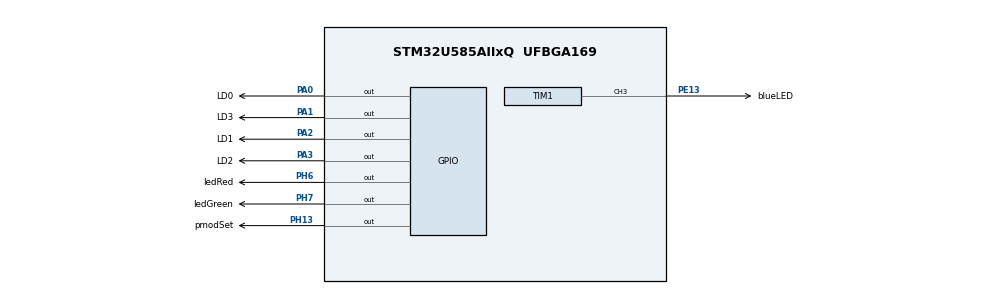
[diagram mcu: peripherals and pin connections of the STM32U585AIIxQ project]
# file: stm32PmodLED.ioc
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CORTEX_M33_NS.userName=CORTEX_M33
Mcu.Family=STM32U5
Mcu.Name=STM32U585AIIxQ
Mcu.Package=UFBGA169
NVIC.PriorityGroup=NVIC_PRIORITYGROUP_4
PA0.GPIO_Label=LD0
PA0.Signal=GPIO_Output
PA1.GPIO_Label=LD3
PA1.Signal=GPIO_Output
PA2.GPIO_Label=LD1
PA2.Signal=GPIO_Output
PA3.GPIO_Label=LD2
PA3.Signal=GPIO_Output
PE13.GPIO_Label=blueLED
PE13.Signal=S_TIM1_CH3
PH13.GPIO_Label=pmodSet
PH13.Signal=GPIO_Output
PH6.GPIO_Label=ledRed
PH6.Signal=GPIO_Output
PH7.GPIO_Label=ledGreen
PH7.Signal=GPIO_Output
ProjectManager.HeapSize=0x200
ProjectManager.StackSize=0x400
ProjectManager.TargetToolchain=STM32CubeIDE
RCC.ADCFreq_Value=16000000
RCC.EPOD_VALUE=4000000
RCC.HSE_VALUE=16000000
RCC.HSI48_VALUE=48000000
RCC.HSI_VALUE=16000000
RCC.LSE_VALUE=32768
RCC.LSIDIV_VALUE=32000
RCC.MSI_VALUE=4000000
RCC.USBFreq_Value=48000000
RCC.VCOOutputFreq_Value=516000000
SH.S_TIM1_CH3.0=TIM1_CH3,PWM Generation3 CH3
TIM1.Channel-PWM\ Generation3\ CH3=TIM_CHANNEL_3
TIM1.PeriodNoDither=999
TIM1.Prescaler=3
VP_LPBAMQUEUE_VS_QUEUE.Mode=QUEUEMODE
VP_LPBAM_VS_SIG1.Mode=SmartRun
VP_LPBAM_VS_SIG4.Mode=LPDMA1
VP_MEMORYMAP_VS_MEMORYMAP.Mode=CurAppReg
VP_PWR_VS_SECSignals.Mode=Security/Privilege
board=custom

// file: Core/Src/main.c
/* USER CODE BEGIN Header */
/**
  ******************************************************************************
  * @file           : main.c
  * @brief          : Main program body
  ******************************************************************************
  * @attention
  *
  * Copyright (c) 2025 STMicroelectronics.
  * All rights reserved.
  *
  * This software is licensed under terms that can be found in the LICENSE file
  * in the root directory of this software component.
  * If no LICENSE file comes with this software, it is provided AS-IS.
  *
  ******************************************************************************
  */
/* USER CODE END Header */
#include "main.h"

TIM_HandleTypeDef htim1;

void SystemClock_Config(void);
static void MX_GPIO_Init(void);
static void MX_TIM1_Init(void);

int main(void)
{

  /* MCU Configuration--------------------------------------------------------*/

  /* Reset of all peripherals, Initializes the Flash interface and the Systick. */
  HAL_Init();

  /* Configure the system clock */
  SystemClock_Config();

  /* Initialize all configured peripherals */
  MX_GPIO_Init();
  MX_TIM1_Init();
  /* USER CODE BEGIN 2 */
  HAL_GPIO_WritePin(GPIOH, pmodSet_Pin, GPIO_PIN_SET);
  HAL_GPIO_WritePin(GPIOA, LD0_Pin|LD3_Pin|LD1_Pin|LD2_Pin, GPIO_PIN_RESET);
  HAL_GPIO_WritePin(GPIOH, ledRed_Pin|ledGreen_Pin, GPIO_PIN_SET);
  /* USER CODE END 2 */

  /* Infinite loop */
  /* USER CODE BEGIN WHILE */
  HAL_TIM_PWM_Start(&htim1, TIM_CHANNEL_3);
  while (1)
  {
    /* USER CODE END WHILE */

    /* USER CODE BEGIN 3 */
	  for(int i = 0; i < 1000; i++)
	  {
		  __HAL_TIM_SET_COMPARE(&htim1, TIM_CHANNEL_3, i);
		  HAL_Delay(1);
	  }
	  for(int i = 1000; i > 0; i--)
	  {
		  __HAL_TIM_SET_COMPARE(&htim1, TIM_CHANNEL_3, i);
		  HAL_Delay(1);
	  }
  }
  /* USER CODE END 3 */
}

void SystemClock_Config(void)
{
  RCC_OscInitTypeDef RCC_OscInitStruct = {0};
  RCC_ClkInitTypeDef RCC_ClkInitStruct = {0};

  /** Configure the main internal regulator output voltage
  */
  if (HAL_PWREx_ControlVoltageScaling(PWR_REGULATOR_VOLTAGE_SCALE4) != HAL_OK)
  {
    Error_Handler();
  }

  /** Initializes the CPU, AHB and APB buses clocks
  */
  RCC_OscInitStruct.OscillatorType = RCC_OSCILLATORTYPE_MSI;
  RCC_OscInitStruct.MSIState = RCC_MSI_ON;
  RCC_OscInitStruct.MSICalibrationValue = RCC_MSICALIBRATION_DEFAULT;
  RCC_OscInitStruct.MSIClockRange = RCC_MSIRANGE_4;
  RCC_OscInitStruct.PLL.PLLState = RCC_PLL_NONE;
  if (HAL_RCC_OscConfig(&RCC_OscInitStruct) != HAL_OK)
  {
    Error_Handler();
  }

  /** Initializes the CPU, AHB and APB buses clocks
  */
  RCC_ClkInitStruct.ClockType = RCC_CLOCKTYPE_HCLK|RCC_CLOCKTYPE_SYSCLK
                              |RCC_CLOCKTYPE_PCLK1|RCC_CLOCKTYPE_PCLK2
                              |RCC_CLOCKTYPE_PCLK3;
  RCC_ClkInitStruct.SYSCLKSource = RCC_SYSCLKSOURCE_MSI;
  RCC_ClkInitStruct.AHBCLKDivider = RCC_SYSCLK_DIV1;
  RCC_ClkInitStruct.APB1CLKDivider = RCC_HCLK_DIV1;
  RCC_ClkInitStruct.APB2CLKDivider = RCC_HCLK_DIV1;
  RCC_ClkInitStruct.APB3CLKDivider = RCC_HCLK_DIV1;

  if (HAL_RCC_ClockConfig(&RCC_ClkInitStruct, FLASH_LATENCY_0) != HAL_OK)
  {
    Error_Handler();
  }
}

static void MX_TIM1_Init(void)
{

  TIM_MasterConfigTypeDef sMasterConfig = {0};
  TIM_OC_InitTypeDef sConfigOC = {0};
  TIM_BreakDeadTimeConfigTypeDef sBreakDeadTimeConfig = {0};

  htim1.Instance = TIM1;
  htim1.Init.Prescaler = 3;
  htim1.Init.CounterMode = TIM_COUNTERMODE_UP;
  htim1.Init.Period = 999;
  htim1.Init.ClockDivision = TIM_CLOCKDIVISION_DIV1;
  htim1.Init.RepetitionCounter = 0;
  htim1.Init.AutoReloadPreload = TIM_AUTORELOAD_PRELOAD_DISABLE;
  if (HAL_TIM_PWM_Init(&htim1) != HAL_OK)
  {
    Error_Handler();
  }
  sMasterConfig.MasterOutputTrigger = TIM_TRGO_RESET;
  sMasterConfig.MasterOutputTrigger2 = TIM_TRGO2_RESET;
  sMasterConfig.MasterSlaveMode = TIM_MASTERSLAVEMODE_DISABLE;
  if (HAL_TIMEx_MasterConfigSynchronization(&htim1, &sMasterConfig) != HAL_OK)
  {
    Error_Handler();
  }
  sConfigOC.OCMode = TIM_OCMODE_PWM1;
  sConfigOC.Pulse = 0;
  sConfigOC.OCPolarity = TIM_OCPOLARITY_HIGH;
  sConfigOC.OCNPolarity = TIM_OCNPOLARITY_HIGH;
  sConfigOC.OCFastMode = TIM_OCFAST_DISABLE;
  sConfigOC.OCIdleState = TIM_OCIDLESTATE_RESET;
  sConfigOC.OCNIdleState = TIM_OCNIDLESTATE_RESET;
  if (HAL_TIM_PWM_ConfigChannel(&htim1, &sConfigOC, TIM_CHANNEL_3) != HAL_OK)
  {
    Error_Handler();
  }
  sBreakDeadTimeConfig.OffStateRunMode = TIM_OSSR_DISABLE;
  sBreakDeadTimeConfig.OffStateIDLEMode = TIM_OSSI_DISABLE;
  sBreakDeadTimeConfig.LockLevel = TIM_LOCKLEVEL_OFF;
  sBreakDeadTimeConfig.DeadTime = 0;
  sBreakDeadTimeConfig.BreakState = TIM_BREAK_DISABLE;
  sBreakDeadTimeConfig.BreakPolarity = TIM_BREAKPOLARITY_HIGH;
  sBreakDeadTimeConfig.BreakFilter = 0;
  sBreakDeadTimeConfig.BreakAFMode = TIM_BREAK_AFMODE_INPUT;
  sBreakDeadTimeConfig.Break2State = TIM_BREAK2_DISABLE;
  sBreakDeadTimeConfig.Break2Polarity = TIM_BREAK2POLARITY_HIGH;
  sBreakDeadTimeConfig.Break2Filter = 0;
  sBreakDeadTimeConfig.Break2AFMode = TIM_BREAK_AFMODE_INPUT;
  sBreakDeadTimeConfig.AutomaticOutput = TIM_AUTOMATICOUTPUT_DISABLE;
  if (HAL_TIMEx_ConfigBreakDeadTime(&htim1, &sBreakDeadTimeConfig) != HAL_OK)
  {
    Error_Handler();
  }
  HAL_TIM_MspPostInit(&htim1);

}

static void MX_GPIO_Init(void)
{
  GPIO_InitTypeDef GPIO_InitStruct = {0};

  /* GPIO Ports Clock Enable */
  __HAL_RCC_GPIOH_CLK_ENABLE();
  __HAL_RCC_GPIOA_CLK_ENABLE();
  __HAL_RCC_GPIOE_CLK_ENABLE();

  /*Configure GPIO pin Output Level */
  HAL_GPIO_WritePin(GPIOH, pmodSet_Pin|ledRed_Pin|ledGreen_Pin, GPIO_PIN_RESET);

  /*Configure GPIO pin Output Level */
  HAL_GPIO_WritePin(GPIOA, LD0_Pin|LD3_Pin|LD1_Pin|LD2_Pin, GPIO_PIN_RESET);

  /*Configure GPIO pins : pmodSet_Pin ledRed_Pin ledGreen_Pin */
  GPIO_InitStruct.Pin = pmodSet_Pin|ledRed_Pin|ledGreen_Pin;
  GPIO_InitStruct.Mode = GPIO_MODE_OUTPUT_PP;
  GPIO_InitStruct.Pull = GPIO_NOPULL;
  GPIO_InitStruct.Speed = GPIO_SPEED_FREQ_LOW;
  HAL_GPIO_Init(GPIOH, &GPIO_InitStruct);

  /*Configure GPIO pins : LD0_Pin LD3_Pin LD1_Pin LD2_Pin */
  GPIO_InitStruct.Pin = LD0_Pin|LD3_Pin|LD1_Pin|LD2_Pin;
  GPIO_InitStruct.Mode = GPIO_MODE_OUTPUT_PP;
  GPIO_InitStruct.Pull = GPIO_NOPULL;
  GPIO_InitStruct.Speed = GPIO_SPEED_FREQ_LOW;
  HAL_GPIO_Init(GPIOA, &GPIO_InitStruct);

}

void Error_Handler(void)
{
  __disable_irq();
  while (1)
  {
  }
}
